# XMC4200 register map
Vendor: Infineon; File version: 1.5.2 (Reference Manual v1.5)
CPU: CM4 r2p0, little endian, MPU, FPU, 6 interrupt priority bits
Registers are 32-bit, read-write, reset 0x0 unless marked. A register's access mark holds for its fields unless they carry their own. Offsets are from the block's base; [hi:lo] are bit positions; {n}, {i} and the like mark numbered series.

## USIC0 — Universal Serial Interface Controller 0
Base 0x40030008
Same registers: USIC1 0x48020008
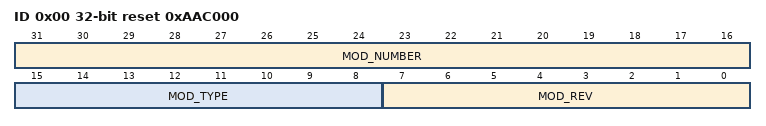
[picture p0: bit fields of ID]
0x00 ID ro reset 0xAAC000 (reset mask 0xFFFFFF00) — Module Identification Register
  [31:16] MOD_NUMBER — Module Number Value
  [15:8] MOD_TYPE — Module Type
  [7:0] MOD_REV — Module Revision Number

## CAN — Controller Area Networks
Base 0x48014000
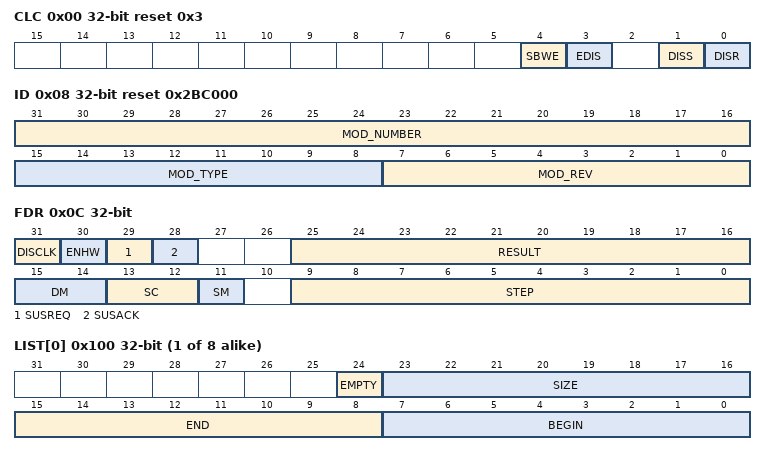
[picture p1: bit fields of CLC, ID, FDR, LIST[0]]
0x00 CLC access per field reset 0x3 — CAN Clock Control Register
  [4] SBWE wo — Module Suspend Bit Write Enable for OCDS
  [3] EDIS rw — Sleep Mode Enable Control
  [1] DISS ro — Module Disable Status Bit
  [0] DISR rw — Module Disable Request Bit
0x08 ID ro reset 0x2BC000 (reset mask 0xFFFFFF00) — Module Identification Register
  [31:16] MOD_NUMBER — Module Number Value
  [15:8] MOD_TYPE — Module Type
    192=Define the module as a 32-bit module
  [7:0] MOD_REV — Module Revision Number
0x0C FDR access per field — CAN Fractional Divider Register
  [31] DISCLK rw — Disable Clock
  [30] ENHW rw — Enable Hardware Clock Control
  [29] SUSREQ ro — Suspend Mode Request
  [28] SUSACK ro — Suspend Mode Acknowledge
  [25:16] RESULT ro — Result Value
  [15:14] DM rw — Divider Mode
  [13:12] SC rw — Suspend Control
  [11] SM rw — Suspend Mode
  [9:0] STEP rw — Step Value
{0x100+4i} LIST[{i}] (i=0..7) ro reset not defined
  [24] EMPTY — List Empty Indication
    0=At least one message object is allocated to list i; 1=No message object is allocated to the list x. List x is empty.
  [23:16] SIZE — List Size
  [15:8] END — List End
  [7:0] BEGIN — List Begin
{0x140+4i} MSPND[{i}] (i=0..7) — Message Pending Register
  [31:0] PND — Message Pending
{0x180+4i} MSID[{i}] (i=0..7) ro reset 0x20 — Message Index Register
  [5:0] INDEX — Message Pending Index
0x1C0 MSIMASK — Message Index Mask Register
  [31:0] IM — Message Index Mask
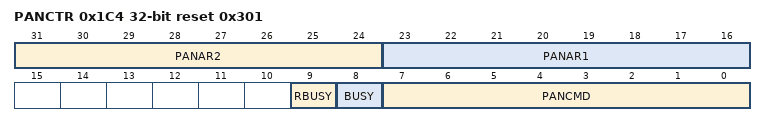
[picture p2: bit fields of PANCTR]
0x1C4 PANCTR access per field reset 0x301 — Panel Control Register
  [31:24] PANAR2 rw — Panel Argument 2
  [23:16] PANAR1 rw — Panel Argument 1
  [9] RBUSY ro — Result Busy Flag
    0=No update of PANAR1 and PANAR2 is scheduled by the list controller; 1=A list command is running (BUSY = 1) that will write results to PANAR1 and PANAR2, but the results are not yet available
  [8] BUSY ro — Panel Busy Flag
    0=Panel has finished command and is ready to accept a new command; 1=Panel operation is in progress
  [7:0] PANCMD rw — Panel Command
0x1C8 MCR — Module Control Register
  [15:12] MPSEL — Message Pending Selector
0x1CC MITR wo — Module Interrupt Trigger Register
  [7:0] IT — Interrupt Trigger

## CCU40 — Capture Compare Unit 4 - Unit 0
Base 0x4000C000
Same registers: CCU41 0x40010000
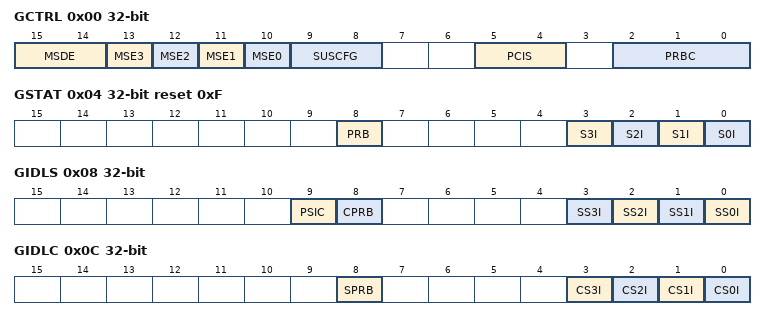
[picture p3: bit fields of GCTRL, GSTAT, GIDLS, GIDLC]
0x00 GCTRL — Global Control Register
  [15:14] MSDE — Multi Channel shadow transfer request configuration
    0=Only the shadow transfer for period and compare values is requested; 1=Shadow transfer for the compare, period and prescaler compare values is requested; 3=Shadow transfer for the compare, period, prescaler and dither compare values is requested
  [n+10] MSE{n} (n=0..3) — Slice {n} Multi Channel shadow transfer enable
    0=Shadow transfer can only be requested by SW; 1=Shadow transfer can be requested via SW and via the CCU4x.MCSS input
  [9:8] SUSCFG — Suspend Mode Configuration
    0=Suspend request ignored. The module never enters in suspend; 1=Stops all the running slices immediately. Safe stop is not applied.; 2=Stops the block immediately and clamps all the outputs to PASSIVE state. Safe stop is applied.; 3=Waits for the roll over of each slice to stop and clamp the slices outputs. Safe stop is applied.
  [5:4] PCIS — Prescaler Input Clock Selection
    0=Module clock; 1=CCU4x.ECLKA; 2=CCU4x.ECLKB; 3=CCU4x.ECLKC
  [2:0] PRBC — Prescaler Clear Configuration
    0=SW only; {v}=GSTATThe register contains the status of the prescaler and each timer slice (idle mode or running)..PRB and prescaler registers are cleared when the Run Bit of CC{v+39} is cleared (v=1..4)
0x04 GSTAT ro reset 0xF — Global Status Register
  [8] PRB — Prescaler Run Bit
    0=Prescaler is stopped; 1=Prescaler is running
  [n] S{n}I (n=0..3) — CC{n+40} IDLE status
    0=Running; 1=Idle
0x08 GIDLS wo — Global Idle Set
  [9] PSIC — Prescaler clear
  [8] CPRB — Prescaler Run Bit Clear
  [n] SS{n}I (n=0..3) — CC{n+40} IDLE mode set
0x0C GIDLC wo — Global Idle Clear
  [8] SPRB — Prescaler Run Bit Set
  [n] CS{n}I (n=0..3) — CC{n+40} IDLE mode clear
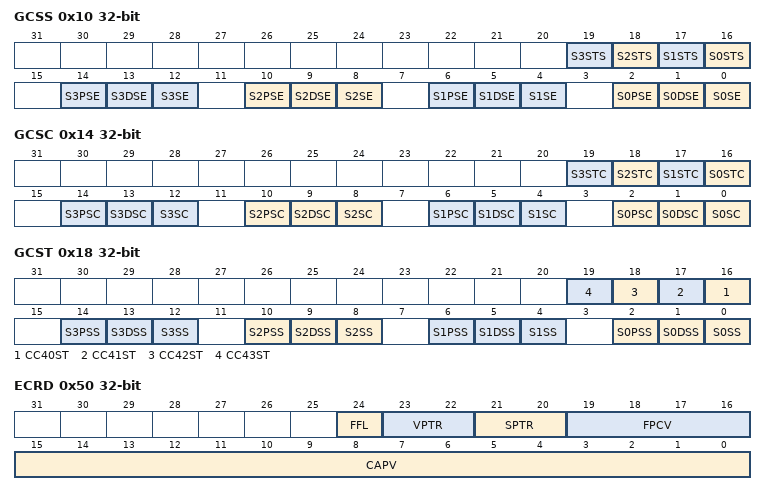
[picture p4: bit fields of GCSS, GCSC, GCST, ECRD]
0x10 GCSS wo — Global Channel Set
  [n+16] S{n}STS (n=0..3) — Slice {n} status bit set
  [4n+2] S{n}PSE (n=0..3) — Slice {n} Prescaler shadow transfer set enable
  [4n+1] S{n}DSE (n=0..3) — Slice {n} Dither shadow transfer set enable
  [4n] S{n}SE (n=0..3) — Slice {n} shadow transfer set enable
0x14 GCSC wo — Global Channel Clear
  [n+16] S{n}STC (n=0..3) — Slice {n} status bit clear
  [4n+2] S{n}PSC (n=0..3) — Slice {n} Prescaler shadow transfer clear
  [4n+1] S{n}DSC (n=0..3) — Slice {n} Dither shadow transfer clear
  [4n] S{n}SC (n=0..3) — Slice {n} shadow transfer clear
0x18 GCST ro — Global Channel Status
  [n-24] CC{n}ST (n=40..43) — Slice {n-40} status bit
  [4n+2] S{n}PSS (n=0..3) — Slice {n} Prescaler shadow transfer status
    0=Prescaler shadow transfer has not been requested; 1=Prescaler shadow transfer has been requested
  [4n+1] S{n}DSS (n=0..3) — Slice {n} Dither shadow transfer status
    0=Dither shadow transfer has not been requested; 1=Dither shadow transfer has been requested
  [4n] S{n}SS (n=0..3) — Slice {n} shadow transfer status
    0=Shadow transfer has not been requested; 1=Shadow transfer has been requested
0x50 ECRD ro read-has-side-effects — Extended Capture Mode Read
  [24] FFL — Full Flag
    0=No new value was captured into this register; 1=A new value has been captured into this register
  [23:22] VPTR — Capture register pointer
    {v}=Capture register {v} (v=0..3)
  [21:20] SPTR — Slice pointer
    {v}=CC{v+40} (v=0..3)
  [19:16] FPCV — Prescaler Capture value
  [15:0] CAPV — Timer Capture Value
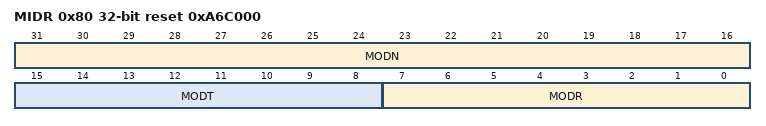
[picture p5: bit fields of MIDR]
0x80 MIDR ro reset 0xA6C000 (reset mask 0xFFFFFF00) — Module Identification
  [31:16] MODN — Module Number
  [15:8] MODT — Module Type
  [7:0] MODR — Module Revision
